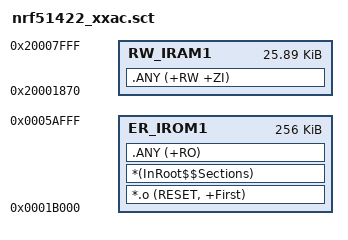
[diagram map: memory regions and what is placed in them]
; *************************************************************
; *** Scatter-Loading Description File generated by uVision ***
; *************************************************************

LR_IROM1 0x0001B000 0x00040000  {    ; load region size_region
  ER_IROM1 0x0001B000 0x00040000  {  ; load address = execution address
   *.o (RESET, +First)
   *(InRoot$$Sections)
   .ANY (+RO)
  }
  RW_IRAM1 0x20001870 0x00006790  {  ; RW data
   .ANY (+RW +ZI)
  }
}

